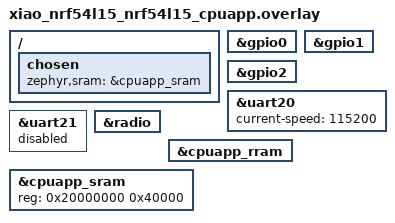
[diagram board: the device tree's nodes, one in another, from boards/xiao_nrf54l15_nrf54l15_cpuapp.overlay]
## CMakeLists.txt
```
#
# Copyright (c) 2025 Nordic Semiconductor ASA
#
# SPDX-License-Identifier: LicenseRef-Nordic-5-Clause
#

cmake_minimum_required(VERSION 3.20.0)

find_package(Zephyr REQUIRED HINTS $ENV{ZEPHYR_BASE})
project(bluepad32_zephyr)

# Main application source
target_sources(app PRIVATE
    src/main.c
)

# Bluetooth layer
target_sources(app PRIVATE
    src/bluetooth/bt_gatt_client.c
)

# TODO: Uncomment as we implement these modules
# target_sources(app PRIVATE
#     src/bluetooth/bt_connection.c
#     src/bluetooth/bt_scan.c
# )
# 
# # Platform layer
# target_sources(app PRIVATE
#     src/platform/uni_platform_zephyr.c
# )
# 
# # Device management
# target_sources(app PRIVATE
#     src/device/uni_hid_device.c
# )
# 
# # Controller abstractions
# target_sources(app PRIVATE
#     src/controller/uni_controller.c
#     src/controller/uni_gamepad.c
#     src/controller/uni_mouse.c
#     src/controller/uni_keyboard.c
# )

# HID Parsers - conditionally compiled based on Kconfig
target_sources_ifdef(CONFIG_BLUEPAD32_PARSER_GENERIC app PRIVATE
    src/parser/uni_hid_parser_generic.c
)

target_sources_ifdef(CONFIG_BLUEPAD32_PARSER_DS4 app PRIVATE
    src/parser/uni_hid_parser_ds4.c
)

target_sources_ifdef(CONFIG_BLUEPAD32_PARSER_SWITCH app PRIVATE
    src/parser/uni_hid_parser_switch.c
)

target_sources_ifdef(CONFIG_BLUEPAD32_PARSER_XBOX app PRIVATE
    src/parser/uni_hid_parser_xboxone.c
)

target_sources_ifdef(CONFIG_BLUEPAD32_PARSER_MOUSE app PRIVATE
    src/parser/uni_hid_parser_mouse.c
)

target_sources_ifdef(CONFIG_BLUEPAD32_PARSER_KEYBOARD app PRIVATE
    src/parser/uni_hid_parser_keyboard.c
)

# Include directories
target_include_directories(app PRIVATE
    src
    src/bluetooth
    src/controller
    src/parser
    src/device
    src/platform
)
```

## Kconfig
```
#
# Copyright (c) 2025 Nordic Semiconductor ASA
#
# SPDX-License-Identifier: LicenseRef-Nordic-5-Clause
#

menuconfig BLUEPAD32
	bool "Bluepad32 Bluetooth Controller Support"
	depends on BT
	select BT_CENTRAL
	select BT_GATT_CLIENT
	select BT_CONN_CTX
	default n
	help
	  Enable Bluepad32 library for Bluetooth gamepad, mouse, and keyboard support.
	  Bluepad32 connects to Bluetooth controllers (as a central device) and provides
	  a unified API for accessing gamepad, mouse, and keyboard input.

if BLUEPAD32

config BLUEPAD32_MAX_DEVICES
	int "Maximum number of connected devices"
	default 4
	range 1 8
	help
	  Maximum number of Bluetooth controllers that can be connected simultaneously.
	  Each device requires memory for connection state, HID reports, and parser data.

choice BLUEPAD32_PLATFORM
	prompt "Target Platform"
	default BLUEPAD32_PLATFORM_ZEPHYR

config BLUEPAD32_PLATFORM_ZEPHYR
	bool "Zephyr RTOS Platform"
	help
	  Use Zephyr RTOS platform implementation with native Bluetooth stack.

endchoice

menu "Controller Parser Support"

config BLUEPAD32_PARSER_GENERIC
	bool "Generic HID Controller Support"
	default y
	help
	  Enable generic HID parser for unknown controllers.
	  This provides basic support for any HID-compliant device.

config BLUEPAD32_PARSER_DS4
	bool "Sony DualShock 4 (PS4) Support"
	default y
	help
	  Enable parser for Sony DualShock 4 controllers.
	  Supports all buttons, analog sticks, triggers, touchpad, and motion sensors.

config BLUEPAD32_PARSER_DS5
	bool "Sony DualSense (PS5) Support"
	default y
	help
	  Enable parser for Sony DualSense controllers.
	  Supports all buttons, analog sticks, triggers, haptic feedback, and adaptive triggers.

config BLUEPAD32_PARSER_SWITCH
	bool "Nintendo Switch Pro Controller Support"
	default y
	help
	  Enable parser for Nintendo Switch Pro controllers.
	  Also supports Joy-Cons (individual or paired).

config BLUEPAD32_PARSER_XBOX
	bool "Xbox Controller Support"
	default y
	help
	  Enable parser for Xbox One and Xbox Series X/S controllers.
	  Supports both Bluetooth and Xbox Wireless Protocol.

config BLUEPAD32_PARSER_WII
	bool "Nintendo Wii Controller Support"
	default n
	help
	  Enable parser for Wii Remote, Nunchuk, and Classic Controller.
	  Includes motion sensor and IR camera support.

config BLUEPAD32_PARSER_8BITDO
	bool "8BitDo Controller Support"
	default n
	help
	  Enable parser for 8BitDo controllers (various models).

config BLUEPAD32_PARSER_MOUSE
	bool "Generic Mouse Support"
	default y
	help
	  Enable parser for Bluetooth mice.
	  Supports buttons, scroll wheel, and movement tracking.

config BLUEPAD32_PARSER_KEYBOARD
	bool "Generic Keyboard Support"
	default y
	help
	  Enable parser for Bluetooth keyboards.
	  Supports standard key events and modifiers.

endmenu # Controller Parser Support

menu "Advanced Options"

config BLUEPAD32_LOG_LEVEL
	int "Bluepad32 Log Level"
	default 3
	range 0 4
	help
	  Set the logging level for Bluepad32 components:
	  0 = OFF, 1 = ERROR, 2 = WARNING, 3 = INFO, 4 = DEBUG

config BLUEPAD32_CONNECTION_TIMEOUT_MS
	int "Device connection timeout (milliseconds)"
	default 10000
	range 5000 30000
	help
	  Maximum time to wait for a device to complete connection and initialization.
	  If the device doesn't respond within this time, the connection is dropped.

config BLUEPAD32_ENABLE_VIRTUAL_DEVICES
	bool "Enable virtual device support"
	default n
	help
	  Allow controllers to create virtual child devices.
	  For example, a DualShock 4 can emulate both a gamepad and a mouse.

config BLUEPAD32_RUMBLE_SUPPORT
	bool "Enable rumble/vibration support"
	default y
	help
	  Enable sending rumble/vibration commands to controllers that support it.

config BLUEPAD32_LED_SUPPORT
	bool "Enable LED control support"
	default y
	help
	  Enable control of controller LEDs (player indicators, lightbar, etc.).

endmenu # Advanced Options

endif # BLUEPAD32

source "Kconfig.zephyr"
```

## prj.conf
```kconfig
#
# Copyright (c) 2025
#
# SPDX-License-Identifier: LicenseRef-Nordic-5-Clause
#
# This is a port for zephyr on the Xiao nrf54l15 board
# Bluetooth Stack - Enable Nordic SoftDevice Controller
CONFIG_BT=y
CONFIG_BT_LL_SOFTDEVICE=y

# BLE Central Role (connect TO controllers)
CONFIG_BT_CENTRAL=y

# Device Identity
CONFIG_BT_DEVICE_NAME="Bluepad32-Zephyr"

# Connection Management
CONFIG_BT_MAX_CONN=4

# GATT Client (discover and subscribe to HID services)
CONFIG_BT_GATT_CLIENT=y

# Security and Bonding (no persistent storage)
CONFIG_BT_SMP=y

# Logging
CONFIG_LOG=y
CONFIG_LOG_MODE_IMMEDIATE=y

# DO NOT CONFIG DK Library for LEDs/Buttons this is not a DK board.
#CONFIG_DK_LIBRARY=y
```

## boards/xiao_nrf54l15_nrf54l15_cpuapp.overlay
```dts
/*
 * Copyright (c) 2025 Nordic Semiconductor ASA
 *
 * SPDX-License-Identifier: LicenseRef-Nordic-5-Clause
 */

/ {
	chosen {
		/* Allocate full 256KB SRAM to cpuapp (no FLPR core used) */
		zephyr,sram = &cpuapp_sram;
	};

	/* Xiao nRF54L15 has led0 and sw0 defined in base board file */
	/* No need to redefine - they already exist */
};

/* Enable GPIO controllers */
&gpio0 {
	status = "okay";
};

&gpio1 {
	status = "okay";
};

&gpio2 {
	status = "okay";
};

/* UART for console output */
&uart20 {
	status = "okay";
	current-speed = <115200>;
};

/* Disable UART21 - not currently connected on Xiao */
&uart21 {
	status = "disabled";
};

/* Enable radio for Bluetooth */
&radio {
	status = "okay";
};

/* RRAM for application and storage */
&cpuapp_rram {
	status = "okay";
};

/* Override SRAM partition to use full 256KB */
&cpuapp_sram {
	reg = <0x20000000 0x40000>; /* 256KB at 0x20000000 */
};
```

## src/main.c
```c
/*
 * Copyright (c) 2025 Nordic Semiconductor ASA
 *
 * SPDX-License-Identifier: LicenseRef-Nordic-5-Clause
 */

#include <zephyr/kernel.h>
#include <zephyr/logging/log.h>
#include <zephyr/bluetooth/bluetooth.h>
#include <zephyr/bluetooth/conn.h>
#include <zephyr/bluetooth/gatt.h>

LOG_MODULE_REGISTER(bluepad32, LOG_LEVEL_DBG);

/* External GATT client API */
extern int bt_gatt_client_init(void);
extern int bt_gatt_client_discover_hid_service(struct bt_conn *conn);

static bool scanning = false;
static struct bt_conn *default_conn = NULL;
static bool connecting = false;
static struct k_work_delayable pairing_work;

/* Forward declarations */
static void scan_start(void);
static void scan_stop(void);
static void start_pairing_work_handler(struct k_work *work);

/* Delayed work to start pairing after connection stabilizes */
static void start_pairing_work_handler(struct k_work *work)
{
	int err;

	if (!default_conn) {
		LOG_ERR("No active connection for pairing");
		return;
	}

	LOG_INF("Starting security upgrade to trigger pairing...");
	err = bt_conn_set_security(default_conn, BT_SECURITY_L2);
	if (err) {
		LOG_ERR("Failed to set security: %d", err);
	}
}

/* Bluetooth connection callbacks */
static void connected(struct bt_conn *conn, uint8_t err)
{
	char addr[BT_ADDR_LE_STR_LEN];
	struct bt_conn_info info;

	connecting = false;

	if (err) {
		LOG_ERR("Connection failed (err 0x%02x)", err);
		/* Resume scanning on connection failure */
		scan_start();
		return;
	}

	bt_addr_le_to_str(bt_conn_get_dst(conn), addr, sizeof(addr));
	LOG_INF("Connected: %s", addr);

	/* Get connection info */
	bt_conn_get_info(conn, &info);
	LOG_INF("Connection interval: %u units (%.2f ms)", 
		info.le.interval, info.le.interval * 1.25);

	/* Store connection reference */
	default_conn = bt_conn_ref(conn);

	/* Stop scanning when connected */
	if (scanning) {
		scan_stop();
	}

	/* Let GATT discovery trigger encryption automatically when needed.
	 * Original Bluepad32 doesn't manually request pairing - the stack
	 * handles it automatically during GATT operations that require encryption.
	 * Start discovery immediately - security will be elevated as needed.
	 */
	LOG_INF("Starting GATT service discovery...");
	err = bt_gatt_client_discover_hid_service(conn);
	if (err) {
		LOG_ERR("Failed to start GATT discovery (err %d)", err);
		bt_conn_disconnect(conn, BT_HCI_ERR_REMOTE_USER_TERM_CONN);
	}
}

static void disconnected(struct bt_conn *conn, uint8_t reason)
{
	char addr[BT_ADDR_LE_STR_LEN];

	bt_addr_le_to_str(bt_conn_get_dst(conn), addr, sizeof(addr));
	LOG_INF("Disconnected: %s (reason 0x%02x)", addr, reason);

	/* Cancel any pending pairing work */
	k_work_cancel_delayable(&pairing_work);

	/* Release connection reference */
	if (default_conn) {
		bt_conn_unref(default_conn);
		default_conn = NULL;
	}

	connecting = false;

	/* Add delay before resuming scan to let stack clean up */
	k_sleep(K_MSEC(500));

	/* Resume scanning */
	scan_start();
}

BT_CONN_CB_DEFINE(conn_callbacks) = {
	.connected = connected,
	.disconnected = disconnected,
};

/* Security/Pairing callbacks */
static void pairing_complete(struct bt_conn *conn, bool bonded)
{
	char addr[BT_ADDR_LE_STR_LEN];

	bt_addr_le_to_str(bt_conn_get_dst(conn), addr, sizeof(addr));
	LOG_INF("Pairing completed: %s, bonded: %d", addr, bonded);

	/* GATT discovery already started in connected() callback.
	 * Pairing happens automatically when GATT operations require it.
	 */
}

static void pairing_failed(struct bt_conn *conn, enum bt_security_err reason)
{
	char addr[BT_ADDR_LE_STR_LEN];

	bt_addr_le_to_str(bt_conn_get_dst(conn), addr, sizeof(addr));
	LOG_ERR("Pairing failed: %s, reason %d", addr, reason);
	
	/* Disconnect on pairing failure */
	bt_conn_disconnect(conn, BT_HCI_ERR_AUTH_FAIL);
}

static void auth_cancel(struct bt_conn *conn)
{
	char addr[BT_ADDR_LE_STR_LEN];

	bt_addr_le_to_str(bt_conn_get_dst(conn), addr, sizeof(addr));
	LOG_WRN("Pairing cancelled: %s", addr);
}

static struct bt_conn_auth_cb auth_callbacks = {
	.cancel = auth_cancel,
};

static struct bt_conn_auth_info_cb auth_info_callbacks = {
	.pairing_complete = pairing_complete,
	.pairing_failed = pairing_failed,
};

/* Scan callback */
static void device_found(const bt_addr_le_t *addr, int8_t rssi, uint8_t type,
			 struct net_buf_simple *ad)
{
	char addr_str[BT_ADDR_LE_STR_LEN];
	int err;

	bt_addr_le_to_str(addr, addr_str, sizeof(addr_str));
	
	/* Filter: Only show devices starting with F4 (Xbox controllers) */
	if (addr->a.val[5] != 0xF4) {
		return;
	}

	LOG_INF("Xbox device found: %s (RSSI %d dBm)", addr_str, rssi);
	LOG_INF("  Address type: %s", addr->type == BT_ADDR_LE_PUBLIC ? "PUBLIC" : "RANDOM");
	LOG_INF("  AD type: 0x%02x, AD data length: %u bytes", type, ad->len);

	/* Skip if already connected or connecting */
	if (default_conn || connecting) {
		LOG_DBG("Already connected/connecting, ignoring");
		return;
	}

	/* Stop scanning before connecting */
	LOG_INF("Stopping scan to initiate connection...");
	scan_stop();

	/* Check if a stale connection exists - if so, skip this attempt */
	struct bt_conn *existing = bt_conn_lookup_addr_le(BT_ID_DEFAULT, addr);
	if (existing) {
		LOG_WRN("Stale connection still exists, skipping connection attempt");
		bt_conn_unref(existing);
		/* Resume scanning after delay */
		k_sleep(K_SECONDS(2));
		scan_start();
		return;
	}

	/* Initiate connection */
	LOG_INF("Connecting to Xbox controller...");
	connecting = true;
	
	struct bt_le_conn_param *param = BT_LE_CONN_PARAM_DEFAULT;
	struct bt_conn *conn = NULL;
	
	err = bt_conn_le_create(addr, BT_CONN_LE_CREATE_CONN, param, &conn);
	if (err) {
		LOG_ERR("Failed to create connection (err %d)", err);
		connecting = false;
		/* Restart scanning on error */
		scan_start();
		return;
	}

	/* Store connection reference */
	default_conn = bt_conn_ref(conn);
	bt_conn_unref(conn);

	LOG_INF("Connection request sent");
}

static void scan_start(void)
{
	int err;

	if (scanning) {
		return;
	}

	/* Bluepad32 uses passive scanning with interval=window=48 (30ms)
	 * Passive scanning doesn't send scan requests, more battery efficient
	 */
	struct bt_le_scan_param scan_param = {
		.type       = BT_LE_SCAN_TYPE_PASSIVE,
		.options    = BT_LE_SCAN_OPT_NONE,
		.interval   = 0x0030,  /* 48 * 0.625ms = 30ms */
		.window     = 0x0030,  /* 48 * 0.625ms = 30ms */
	};

	LOG_DBG("Scan parameters: type=%s interval=%u window=%u",
		scan_param.type == BT_LE_SCAN_TYPE_ACTIVE ? "ACTIVE" : "PASSIVE",
		scan_param.interval, scan_param.window);

	err = bt_le_scan_start(&scan_param, device_found);
	if (err) {
		LOG_ERR("Scanning failed to start (err %d)", err);
		return;
	}

	scanning = true;
	LOG_INF("Scanning started");
	LOG_DBG("Looking for BLE HID devices (game controllers)...");
}

static void scan_stop(void)
{
	int err;

	if (!scanning) {
		return;
	}

	err = bt_le_scan_stop();
	if (err) {
		LOG_ERR("Failed to stop scanning (err %d)", err);
		return;
	}

	scanning = false;
	LOG_INF("Scanning stopped");
}

int main(void)
{
	int err;

	LOG_INF("Bluepad32 for Zephyr starting...");

	/* Initialize delayed work for pairing */
	k_work_init_delayable(&pairing_work, start_pairing_work_handler);

	/* Initialize Bluetooth subsystem */
	err = bt_enable(NULL);
	if (err) {
		LOG_ERR("Bluetooth init failed (err %d)", err);
		return 0;
	}

	/* Register authentication callbacks */
	err = bt_conn_auth_cb_register(&auth_callbacks);
	if (err) {
		LOG_ERR("Failed to register auth callbacks (err %d)", err);
		return 0;
	}

	err = bt_conn_auth_info_cb_register(&auth_info_callbacks);
	if (err) {
		LOG_ERR("Failed to register auth info callbacks (err %d)", err);
		return 0;
	}

	LOG_INF("Bluetooth initialized");
	
	/* Initialize GATT client module */
	err = bt_gatt_client_init();
	if (err) {
		LOG_ERR("GATT client init failed (err %d)", err);
		return 0;
	}
	
	LOG_INF("Starting BLE scan for HID devices...");

	/* Start scanning for HID devices */
	scan_start();

	/* Main loop */
	while (1) {
		k_sleep(K_SECONDS(1));
		/* TODO: Process controller input */
	}

	return 0;
}
```
